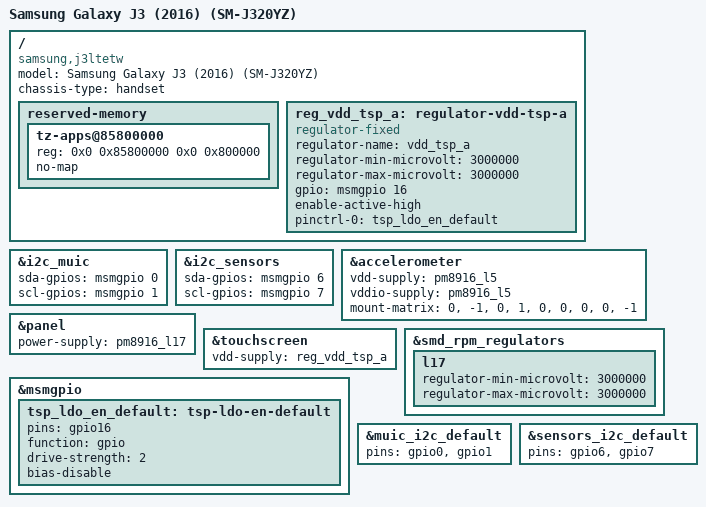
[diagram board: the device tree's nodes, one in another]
// SPDX-License-Identifier: GPL-2.0-only

/dts-v1/;

#include "msm8916-samsung-j5-common.dtsi"

/ {
	model = "Samsung Galaxy J3 (2016) (SM-J320YZ)";
	compatible = "samsung,j3ltetw", "qcom,msm8916";
	chassis-type = "handset";

	reserved-memory {
		/delete-node/ tz-apps@85500000;

		/* Additional memory used by Samsung firmware modifications */
		tz-apps@85800000 {
			reg = <0x0 0x85800000 0x0 0x800000>;
			no-map;
		};
	};

	/delete-node/ gpio-hall-sensor;

	reg_vdd_tsp_a: regulator-vdd-tsp-a {
		compatible = "regulator-fixed";
		regulator-name = "vdd_tsp_a";
		regulator-min-microvolt = <3000000>;
		regulator-max-microvolt = <3000000>;

		gpio = <&msmgpio 16 GPIO_ACTIVE_HIGH>;
		enable-active-high;

		pinctrl-names = "default";
		pinctrl-0 = <&tsp_ldo_en_default>;
	};
};

&i2c_muic {
	sda-gpios = <&msmgpio 0 (GPIO_ACTIVE_HIGH|GPIO_OPEN_DRAIN)>;
	scl-gpios = <&msmgpio 1 (GPIO_ACTIVE_HIGH|GPIO_OPEN_DRAIN)>;
};

&i2c_sensors {
	sda-gpios = <&msmgpio 6 (GPIO_ACTIVE_HIGH|GPIO_OPEN_DRAIN)>;
	scl-gpios = <&msmgpio 7 (GPIO_ACTIVE_HIGH|GPIO_OPEN_DRAIN)>;
};

&accelerometer {
	vdd-supply = <&pm8916_l5>;
	vddio-supply = <&pm8916_l5>;

	mount-matrix = "0", "-1", "0",
		       "1", "0", "0",
		       "0", "0", "-1";
};

&panel {
	/* HACK l17 is a quirk to power up panel */
	power-supply = <&pm8916_l17>;
};

&touchscreen {
	vdd-supply = <&reg_vdd_tsp_a>;
};

&smd_rpm_regulators {
	l17 {
		regulator-min-microvolt = <3000000>;
		regulator-max-microvolt = <3000000>;
	};
};

&msmgpio {
	tsp_ldo_en_default: tsp-ldo-en-default {
		pins = "gpio16";
		function = "gpio";

		drive-strength = <2>;
		bias-disable;
	};
};

&muic_i2c_default {
	pins = "gpio0", "gpio1";
};

&sensors_i2c_default {
	pins = "gpio6", "gpio7";
};
